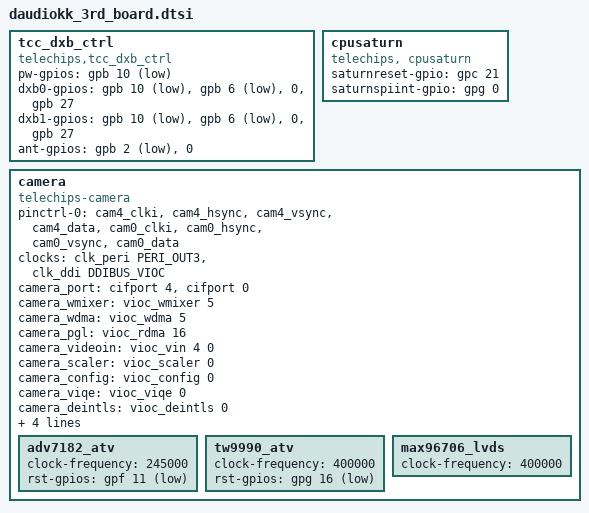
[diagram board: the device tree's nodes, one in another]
	tcc_dxb_ctrl {
		compatible = "telechips,tcc_dxb_ctrl";
		/* DAUDIO BEGIN */
		/*
		pw-gpios   = <&gpext2 27 0>;
		dxb0-gpios = <&gpext2 30 0>, <&gpext2 28 0>, <&gpe 8 0>, <&gpe 1 0>;
		dxb1-gpios = <&gpext2 31 0>, <&gpext2 29 0>, <&gpe 9 0>, <&gpe 17 0>;
		ant-gpios  = <0>, <0>;
		*/
		pw-gpios   = <&gpb 10 1>;
		dxb0-gpios = <&gpb 10 1>, <&gpb 6 1>, <0>, <&gpb 27 0>;
		dxb1-gpios = <&gpb 10 1>, <&gpb 6 1>, <0>, <&gpb 27 0>;
		ant-gpios  = <&gpb 2 1>, <0>;
		/* DAUDIO END */
	};


	/* DAUDIO BEGIN */
	//CPU Saturn reset
	cpusaturn {
		compatible = "telechips, cpusaturn";
		saturnreset-gpio = <&gpc 21 0>; 
		saturnspiint-gpio = <&gpg 0 0>; 
	};

	camera {
		compatible = "telechips-camera";
		status = "okay";
		pinctrl-names = "default";
		pinctrl-0 = <&cam4_clki &cam4_hsync &cam4_vsync &cam4_data &cam0_clki &cam0_hsync &cam0_vsync &cam0_data>;
		clocks = <&clk_peri PERI_OUT3 &clk_ddi DDIBUS_VIOC>;
		camera_port = <&cifport 4>, <&cifport 0>;
		camera_wmixer = <&vioc_wmixer 5>;
		camera_wdma = <&vioc_wdma 5>;
		camera_pgl = <&vioc_rdma 16>;
		camera_videoin = <&vioc_vin 4 0>;
		camera_scaler = <&vioc_scaler 0>;
		camera_config = <&vioc_config 0>;
		camera_viqe = <&vioc_viqe 0>;
		camera_deintls = <&vioc_deintls 0>;
		camera_fifo = <&vioc_fifo 0>;
		camera_viqe_set = <&viqe_hidden>;
		camera_gear-gpios = <&gpe 8 0>;
		rst-gpios = <&gpg 16 0>;

		// support image sensor module list
		adv7182_atv{
			clock-frequency = <245000>;
			rst-gpios = <&gpf 11 1>;
		};

		/* DAUDIO BEGIN */
		tw9990_atv{
			clock-frequency = <400000>;
			rst-gpios = <&gpg 16 1>;
		};	

		max96706_lvds{
			clock-frequency = <400000>;
		};
		/* DAUDIO END */
	};


